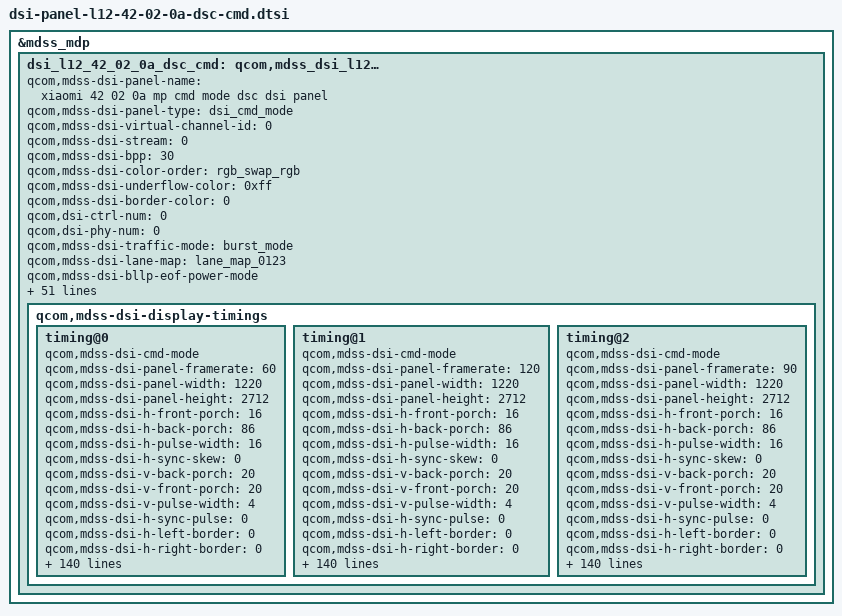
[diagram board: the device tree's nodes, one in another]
&mdss_mdp {
	dsi_l12_42_02_0a_dsc_cmd: qcom,mdss_dsi_l12_42_02_0a_dsc_cmd {
		qcom,mdss-dsi-panel-name = "xiaomi 42 02 0a mp cmd mode dsc dsi panel";
		qcom,mdss-dsi-panel-type = "dsi_cmd_mode";
		qcom,mdss-dsi-virtual-channel-id = <0>;
		qcom,mdss-dsi-stream = <0>;
		qcom,mdss-dsi-bpp = <30>;
		qcom,mdss-dsi-color-order = "rgb_swap_rgb";
		qcom,mdss-dsi-underflow-color = <0xff>;
		qcom,mdss-dsi-border-color = <0>;

		qcom,dsi-ctrl-num = <0>;
		qcom,dsi-phy-num = <0>;

		qcom,mdss-dsi-traffic-mode = "burst_mode";
		qcom,mdss-dsi-lane-map = "lane_map_0123";
		qcom,mdss-dsi-bllp-eof-power-mode;
		qcom,mdss-dsi-bllp-power-mode;
		qcom,mdss-dsi-lane-0-state;
		qcom,mdss-dsi-lane-1-state;
		qcom,mdss-dsi-lane-2-state;
		qcom,mdss-dsi-lane-3-state;
		qcom,mdss-dsi-dma-trigger = "trigger_sw";
		qcom,mdss-dsi-mdp-trigger = "none";
		qcom,mdss-dsi-reset-sequence =  <1 11>, <0 1>, <1 11>;
		qcom,mdss-pan-physical-width-dimension = <695>;
		qcom,mdss-pan-physical-height-dimension = <1545>;
		qcom,mdss-dsi-te-pin-select = <1>;
		qcom,mdss-dsi-wr-mem-start = <0x2c>;
		qcom,mdss-dsi-wr-mem-continue = <0x3c>;
		qcom,mdss-dsi-te-dcs-command = <1>;
		qcom,mdss-dsi-te-check-enable;
		qcom,mdss-dsi-te-using-te-pin;
		qcom,mdss-dsi-tx-eot-append;
		qcom,mdss-dsi-lp11-init;

		qcom,mdss-dsi-bl-inverted-dbv;
		qcom,bl-update-flag = "delay_until_first_frame";
		qcom,mdss-dsi-panel-mode-switch;

		qcom,mdss-dsi-panel-hdr-enabled;
		qcom,mdss-dsi-panel-hdr-color-primaries = <14500 15500 32000 17000 15500 30000 8000 3000>;
		qcom,mdss-dsi-panel-peak-brightness = <4200000>;
		qcom,mdss-dsi-panel-blackness-level = <3230>;
		qcom,mdss-dsi-dma-schedule-line = <1>;
		qcom,mdss-dsi-dma-schedule-window = <10>;

		qcom,mdss-dsi-display-timings {
			/* 60 Hz */
			timing@0{
				qcom,mdss-dsi-cmd-mode;
				qcom,mdss-dsi-panel-framerate = <60>;
				qcom,mdss-dsi-panel-width = <1220>;
				qcom,mdss-dsi-panel-height = <2712>;
				qcom,mdss-dsi-h-front-porch = <16>;
				qcom,mdss-dsi-h-back-porch = <86>;
				qcom,mdss-dsi-h-pulse-width = <16>;
				qcom,mdss-dsi-h-sync-skew = <0>;
				qcom,mdss-dsi-v-back-porch = <20>;
				qcom,mdss-dsi-v-front-porch = <20>;
				qcom,mdss-dsi-v-pulse-width = <4>;
				qcom,mdss-dsi-h-sync-pulse = <0>;
				qcom,mdss-dsi-h-left-border = <0>;
				qcom,mdss-dsi-h-right-border = <0>;
				qcom,mdss-dsi-v-top-border = <0>;
				qcom,mdss-dsi-v-bottom-border = <0>;
				qcom,mdss-dsi-panel-clockrate = <1100000000>;
				qcom,mdss-dsi-panel-jitter = <0x5 0x1>;
				qcom,mdss-mdp-transfer-time-us = <7300>;
				qcom,mdss-dsi-on-command = [
					/* Page 0 */
					39 00 00 00 00 00 06 F0 55 AA 52 08 00
					/* AVDD to 7.3V */
					15 00 00 40 00 00 02 6F 06
					15 00 00 40 00 00 02 B5 2C
					15 00 00 40 00 00 02 6F 0C
					15 00 00 00 00 00 02 B5 2C
					/* Page 3 */
					39 00 00 40 00 00 06 F0 55 AA 52 08 03
					/* Enable EQ in EM-CK AA */
					39 00 00 00 00 00 1E B0
						0F 00 00 0F 00 02 0F 00 00 0F 00 00 0F 00 00 0F
						00 00 0F 00 00 0F 00 00 0F 00 00 0F 00
					/* Set VGLO in SCAN-CK Blanking */
					39 00 00 40 00 00 06 F0 55 AA 52 08 05
					39 00 00 40 00 00 04 D0 00 07 10
					39 00 00 40 00 00 05 E0 00 0A 9E 02
					39 00 00 40 00 00 06 F0 55 AA 52 08 06
					39 00 00 40 00 00 06 B1 32 31 0F 32 31
					15 00 00 40 00 00 02 B3 0E
					39 00 00 40 00 00 06 B7 32 31 0F 32 31
					15 00 00 00 00 00 02 B9 0E
					/* RCN setting */
					39 00 00 40 00 00 05 FF AA 55 A5 80
					15 00 00 40 00 00 02 6F 1D
					15 00 00 40 00 00 02 F2 05
					39 00 00 40 00 00 06 F0 55 AA 52 08 00
					15 00 00 40 00 00 02 6F 1C
					39 00 00 40 00 00 04 C0 03 12 11
					39 00 00 40 00 00 06 F0 55 AA 52 08 00
					15 00 00 00 00 00 02 03 01
					/* VBP&VFP*/
					39 00 00 00 00 00 05 3B 00 14 00 14
					/* VESA ON */
					15 00 00 00 00 00 02 90 11
					/* VESA Edition */
					39 00 00 40 00 00 13 91
						AB 28 00 0C C2 00 02 32 01 31 00 08 08 BB 07 7B
						10 F0
					15 00 00 00 00 00 02 2C 00
					/* BACKLIGHT ON */
					39 00 00 40 00 00 05 51 00 00 0F FE
					15 00 00 00 00 00 02 53 20
					/* TE ON */
					15 00 00 00 00 00 02 35 00
					/* CASET/RASET Setting 1220*2712 */
					39 00 00 40 00 00 05 2A 00 00 04 C3
					39 00 00 00 00 00 05 2B 00 00 0A 97
					/* 60 Hz */
					15 00 00 40 00 00 02 2F 02
					15 00 00 40 00 00 02 5F 01
					39 00 00 40 00 00 06 F0 55 AA 52 08 00
					15 00 00 40 00 00 02 6F 09
					15 00 00 40 00 00 02 C0 00
					39 00 00 40 00 00 06 F0 55 AA 52 08 02
					15 00 00 40 00 00 02 CC 30
					15 00 00 00 14 00 02 CE 01
					15 00 00 00 00 00 02 CC 00
					/* OSC calibration */
					39 00 00 40 00 00 06 F0 55 AA 52 08 01
					39 00 00 00 00 00 08 C3 9B 01 94 D0 22 02 00
					/* round on */
					39 00 00 40 00 00 06 F0 55 AA 52 08 07
					39 00 00 00 00 00 02 C0 01
					/* ESD Error Flag, Normal High, Error Low */
					39 00 00 40 00 00 06 F0 55 AA 52 08 00
					39 00 00 40 00 00 02 6F 05
					39 00 00 00 00 00 02 BE 88
					/* Source-on-test */
					39 00 00 40 00 00 06 F0 55 AA 52 08 00
					15 00 00 40 00 00 02 6F 02
					15 00 00 00 00 00 02 C1 D8
					/* enter aod with no black */
					39 00 00 40 00 00 05 FF AA 55 A5 80
					15 00 00 40 00 00 02 6F 61
					15 00 00 00 00 00 02 F3 80
					/* demura */
					39 00 00 40 00 00 06 F0 55 AA 52 08 04
					15 00 00 40 00 00 02 6F 0D
					15 00 00 00 00 00 02 CA 05
					/* dimming step timing */
					39 01 00 40 00 00 06 F0 55 AA 52 08 00
					15 01 00 40 00 00 02 B2 98
					15 01 00 40 00 00 02 6F 02
					39 01 00 00 00 00 03 B2 0A 0A
					/* Sleep Out */
					05 00 00 00 78 00 02 11 00
					/* Display On */
					05 00 00 00 00 00 02 29 00
				];
				qcom,mdss-dsi-off-command = [
					05 00 00 00 14 00 02 28 00
					05 00 00 00 64 00 02 10 00
				];
				qcom,mdss-dsi-on-command-state = "dsi_lp_mode";
				qcom,mdss-dsi-off-command-state = "dsi_lp_mode";

				qcom,mdss-dsi-timing-switch-command = [
					/* 60 Hz cmd_1 */
					15 00 00 00 00 00 02 2F 02
					39 00 00 40 00 00 06 F0 55 AA 52 08 00
					15 00 00 40 00 00 02 6F 09
					15 00 00 40 00 00 02 C0 00
					39 00 00 40 00 00 06 F0 55 AA 52 08 02
					15 00 00 40 00 00 02 CC 30
					15 00 00 00 14 00 02 CE 01
					15 00 00 00 00 00 02 CC 00
				];
				qcom,mdss-dsi-timing-switch-command-update = <0xC0 3 1>;
				qcom,mdss-dsi-timing-switch-command-state = "dsi_hs_mode";

				qcom,mdss-dsi-nolp-command = [
					39 00 00 00 00 00 06 F0 55 AA 52 08 00
					39 00 00 00 00 00 02 B2 98
					39 00 00 00 00 00 02 65 00
					39 00 00 00 32 00 01 38
					39 00 00 00 00 00 01 2C
				];
				qcom,mdss-dsi-nolp-command-state = "dsi_lp_mode";

				qcom,compression-mode = "dsc";
				qcom,mdss-dsc-config-by-manufacture-cmd;
				qcom,mdss-dsc-version = <0x11>;
				qcom,mdss-dsc-scr-version = <0x0>;
				qcom,mdss-dsc-slice-height = <12>;
				qcom,mdss-dsc-slice-width = <610>;
				qcom,mdss-dsc-slice-per-pkt = <2>;
				qcom,mdss-dsc-bit-per-component = <10>;
				qcom,mdss-dsc-bit-per-pixel = <8>;
				qcom,mdss-dsc-block-prediction-enable;
			};

			/* 120 Hz */
			timing@1{
				qcom,mdss-dsi-cmd-mode;
				qcom,mdss-dsi-panel-framerate = <120>;
				qcom,mdss-dsi-panel-width = <1220>;
				qcom,mdss-dsi-panel-height = <2712>;
				qcom,mdss-dsi-h-front-porch = <16>;
				qcom,mdss-dsi-h-back-porch = <86>;
				qcom,mdss-dsi-h-pulse-width = <16>;
				qcom,mdss-dsi-h-sync-skew = <0>;
				qcom,mdss-dsi-v-back-porch = <20>;
				qcom,mdss-dsi-v-front-porch = <20>;
				qcom,mdss-dsi-v-pulse-width = <4>;
				qcom,mdss-dsi-h-sync-pulse = <0>;
				qcom,mdss-dsi-h-left-border = <0>;
				qcom,mdss-dsi-h-right-border = <0>;
				qcom,mdss-dsi-v-top-border = <0>;
				qcom,mdss-dsi-v-bottom-border = <0>;
				qcom,mdss-dsi-panel-clockrate = <1100000000>;
				qcom,mdss-dsi-panel-jitter = <0x5 0x1>;
				qcom,mdss-mdp-transfer-time-us = <7300>;
				qcom,mdss-dsi-on-command = [
					/* Page 0 */
					39 00 00 00 00 00 06 F0 55 AA 52 08 00
					/* AVDD to 7.3V */
					15 00 00 40 00 00 02 6F 06
					15 00 00 40 00 00 02 B5 2C
					15 00 00 40 00 00 02 6F 0C
					15 00 00 00 00 00 02 B5 2C
					/* Page 3 */
					39 00 00 40 00 00 06 F0 55 AA 52 08 03
					/* Enable EQ in EM-CK AA */
					39 00 00 00 00 00 1E B0
						0F 00 00 0F 00 02 0F 00 00 0F 00 00 0F 00 00 0F
						00 00 0F 00 00 0F 00 00 0F 00 00 0F 00
					/* Set VGLO in SCAN-CK Blanking */
					39 00 00 40 00 00 06 F0 55 AA 52 08 05
					39 00 00 40 00 00 04 D0 00 07 10
					39 00 00 40 00 00 05 E0 00 0A 9E 02
					39 00 00 40 00 00 06 F0 55 AA 52 08 06
					39 00 00 40 00 00 06 B1 32 31 0F 32 31
					15 00 00 40 00 00 02 B3 0E
					39 00 00 40 00 00 06 B7 32 31 0F 32 31
					15 00 00 00 00 00 02 B9 0E
					/* RCN setting */
					39 00 00 40 00 00 05 FF AA 55 A5 80
					15 00 00 40 00 00 02 6F 1D
					15 00 00 40 00 00 02 F2 05
					39 00 00 40 00 00 06 F0 55 AA 52 08 00
					15 00 00 40 00 00 02 6F 1C
					39 00 00 40 00 00 04 C0 03 12 11
					39 00 00 40 00 00 06 F0 55 AA 52 08 00
					15 00 00 00 00 00 02 03 01
					/* VBP&VFP*/
					39 00 00 00 00 00 05 3B 00 14 00 14
					/* VESA ON */
					15 00 00 00 00 00 02 90 11
					/* VESA Edition */
					39 00 00 40 00 00 13 91
						AB 28 00 0C C2 00 02 32 01 31 00 08 08 BB 07 7B
						10 F0
					15 00 00 00 00 00 02 2C 00
					/* BACKLIGHT ON */
					39 00 00 40 00 00 05 51 00 00 0F FE
					15 00 00 00 00 00 02 53 20
					/* TE ON */
					15 00 00 00 00 00 02 35 00
					/* CASET/RASET Setting 1220*2712 */
					39 00 00 40 00 00 05 2A 00 00 04 C3
					39 00 00 00 00 00 05 2B 00 00 0A 97
					/* 120 Hz */
					15 00 00 40 00 00 02 2F 03
					15 00 00 40 00 00 02 5F 01
					39 00 00 40 00 00 06 F0 55 AA 52 08 00
					15 00 00 40 00 00 02 6F 0A
					15 00 00 40 00 00 02 C0 20
					39 00 00 40 00 00 06 F0 55 AA 52 08 02
					15 00 00 40 00 00 02 CC 30
					15 00 00 00 14 00 02 CE 01
					15 00 00 00 00 00 02 CC 00
					/* OSC calibration */
					39 00 00 40 00 00 06 F0 55 AA 52 08 01
					39 00 00 00 00 00 08 C3 9B 01 94 D0 22 02 00
					/* round on */
					39 00 00 40 00 00 06 F0 55 AA 52 08 07
					39 00 00 00 00 00 02 C0 01
					/* ESD Error Flag, Normal High, Error Low */
					39 00 00 40 00 00 06 F0 55 AA 52 08 00
					39 00 00 40 00 00 02 6F 05
					39 00 00 00 00 00 02 BE 88
					/* Source-on-test */
					39 00 00 40 00 00 06 F0 55 AA 52 08 00
					15 00 00 40 00 00 02 6F 02
					15 00 00 00 00 00 02 C1 D8
					/* enter aod with no black */
					39 00 00 40 00 00 05 FF AA 55 A5 80
					15 00 00 40 00 00 02 6F 61
					15 00 00 00 00 00 02 F3 80
					/* demura */
					39 00 00 40 00 00 06 F0 55 AA 52 08 04
					15 00 00 40 00 00 02 6F 0D
					15 00 00 00 00 00 02 CA 05
					/* dimming step timing */
					39 01 00 40 00 00 06 F0 55 AA 52 08 00
					15 01 00 40 00 00 02 B2 98
					15 01 00 40 00 00 02 6F 02
					39 01 00 00 00 00 03 B2 0A 0A
					/* Sleep Out */
					05 00 00 00 78 00 02 11 00
					/* Display On */
					05 00 00 00 00 00 02 29 00
				];
				qcom,mdss-dsi-off-command = [
					05 00 00 00 14 00 02 28 00
					05 00 00 00 64 00 02 10 00
				];
				qcom,mdss-dsi-on-command-state = "dsi_lp_mode";
				qcom,mdss-dsi-off-command-state = "dsi_lp_mode";

				qcom,mdss-dsi-timing-switch-command = [
					/* 120 Hz cmd_1 */
					15 00 00 00 00 00 02 2F 03
					39 00 00 40 00 00 06 F0 55 AA 52 08 00
					15 00 00 40 00 00 02 6F 0A
					15 00 00 40 00 00 02 C0 20
					39 00 00 40 00 00 06 F0 55 AA 52 08 02
					15 00 00 40 00 00 02 CC 30
					15 00 00 00 0A 00 02 CE 01
					15 00 00 00 00 00 02 CC 00
				];
				qcom,mdss-dsi-timing-switch-command-update = <0xC0 3 1>;
				qcom,mdss-dsi-timing-switch-command-state = "dsi_hs_mode";

				qcom,mdss-dsi-nolp-command = [
					39 00 00 00 00 00 06 F0 55 AA 52 08 00
					39 00 00 00 00 00 02 B2 98
					39 00 00 00 00 00 02 65 00
					39 00 00 00 32 00 01 38
					39 00 00 00 00 00 01 2C
				];
				qcom,mdss-dsi-nolp-command-state = "dsi_lp_mode";

				qcom,compression-mode = "dsc";
				qcom,mdss-dsc-config-by-manufacture-cmd;
				qcom,mdss-dsc-version = <0x11>;
				qcom,mdss-dsc-scr-version = <0x0>;
				qcom,mdss-dsc-slice-height = <12>;
				qcom,mdss-dsc-slice-width = <610>;
				qcom,mdss-dsc-slice-per-pkt = <2>;
				qcom,mdss-dsc-bit-per-component = <10>;
				qcom,mdss-dsc-bit-per-pixel = <8>;
				qcom,mdss-dsc-block-prediction-enable;
			};

			/* 90 Hz */
			timing@2{
				qcom,mdss-dsi-cmd-mode;
				qcom,mdss-dsi-panel-framerate = <90>;
				qcom,mdss-dsi-panel-width = <1220>;
				qcom,mdss-dsi-panel-height = <2712>;
				qcom,mdss-dsi-h-front-porch = <16>;
				qcom,mdss-dsi-h-back-porch = <86>;
				qcom,mdss-dsi-h-pulse-width = <16>;
				qcom,mdss-dsi-h-sync-skew = <0>;
				qcom,mdss-dsi-v-back-porch = <20>;
				qcom,mdss-dsi-v-front-porch = <20>;
				qcom,mdss-dsi-v-pulse-width = <4>;
				qcom,mdss-dsi-h-sync-pulse = <0>;
				qcom,mdss-dsi-h-left-border = <0>;
				qcom,mdss-dsi-h-right-border = <0>;
				qcom,mdss-dsi-v-top-border = <0>;
				qcom,mdss-dsi-v-bottom-border = <0>;
				qcom,mdss-dsi-panel-clockrate = <1100000000>;
				qcom,mdss-dsi-panel-jitter = <0x5 0x1>;
				qcom,mdss-mdp-transfer-time-us = <7300>;
				qcom,mdss-dsi-on-command = [
					/* Page 0 */
					39 00 00 00 00 00 06 F0 55 AA 52 08 00
					/* AVDD to 7.3V */
					15 00 00 40 00 00 02 6F 06
					15 00 00 40 00 00 02 B5 2C
					15 00 00 40 00 00 02 6F 0C
					15 00 00 00 00 00 02 B5 2C
					/* Page 3 */
					39 00 00 40 00 00 06 F0 55 AA 52 08 03
					/* Enable EQ in EM-CK AA */
					39 00 00 00 00 00 1E B0
						0F 00 00 0F 00 02 0F 00 00 0F 00 00 0F 00 00 0F
						00 00 0F 00 00 0F 00 00 0F 00 00 0F 00
					/* Set VGLO in SCAN-CK Blanking */
					39 00 00 40 00 00 06 F0 55 AA 52 08 05
					39 00 00 40 00 00 04 D0 00 07 10
					39 00 00 40 00 00 05 E0 00 0A 9E 02
					39 00 00 40 00 00 06 F0 55 AA 52 08 06
					39 00 00 40 00 00 06 B1 32 31 0F 32 31
					15 00 00 40 00 00 02 B3 0E
					39 00 00 40 00 00 06 B7 32 31 0F 32 31
					15 00 00 00 00 00 02 B9 0E
					/* RCN setting */
					39 00 00 40 00 00 05 FF AA 55 A5 80
					15 00 00 40 00 00 02 6F 1D
					15 00 00 40 00 00 02 F2 05
					39 00 00 40 00 00 06 F0 55 AA 52 08 00
					15 00 00 40 00 00 02 6F 1C
					39 00 00 40 00 00 04 C0 03 12 11
					39 00 00 40 00 00 06 F0 55 AA 52 08 00
					15 00 00 00 00 00 02 03 01
					/* VBP&VFP*/
					39 00 00 00 00 00 05 3B 00 14 00 14
					/* VESA ON */
					15 00 00 00 00 00 02 90 11
					/* VESA Edition */
					39 00 00 40 00 00 13 91
						AB 28 00 0C C2 00 02 32 01 31 00 08 08 BB 07 7B
						10 F0
					15 00 00 00 00 00 02 2C 00
					/* BACKLIGHT ON */
					39 00 00 40 00 00 05 51 00 00 0F FE
					15 00 00 00 00 00 02 53 20
					/* TE ON */
					15 00 00 00 00 00 02 35 00
					/* CASET/RASET Setting 1220*2712 */
					39 00 00 40 00 00 05 2A 00 00 04 C3
					39 00 00 40 00 00 05 2B 00 00 0A 97
					/* 90 Hz */
					15 00 00 40 00 00 02 2F 04
					15 00 00 40 00 00 02 5F 01
					39 00 00 40 00 00 06 F0 55 AA 52 08 00
					15 00 00 40 00 00 02 6F 0B
					15 00 00 40 00 00 02 C0 20
					39 00 00 40 00 00 06 F0 55 AA 52 08 02
					15 00 00 40 00 00 02 CC 30
					15 00 00 00 14 00 02 CE 01
					15 00 00 00 00 00 02 CC 00
					/* OSC calibration */
					39 00 00 40 00 00 06 F0 55 AA 52 08 01
					39 00 00 00 00 00 08 C3 9B 01 94 D0 22 02 00
					/* round on */
					39 00 00 40 00 00 06 F0 55 AA 52 08 07
					39 00 00 00 00 00 02 C0 01
					/* ESD Error Flag, Normal High, Error Low */
					39 00 00 40 00 00 06 F0 55 AA 52 08 00
					39 00 00 40 00 00 02 6F 05
					39 00 00 00 00 00 02 BE 88
					/* Source-on-test */
					39 00 00 40 00 00 06 F0 55 AA 52 08 00
					15 00 00 40 00 00 02 6F 02
					15 00 00 00 00 00 02 C1 D8
					/* enter aod with no black */
					39 00 00 40 00 00 05 FF AA 55 A5 80
					15 00 00 40 00 00 02 6F 61
					15 00 00 00 00 00 02 F3 80
					/* demura */
					39 00 00 40 00 00 06 F0 55 AA 52 08 04
					15 00 00 40 00 00 02 6F 0D
					15 00 00 00 00 00 02 CA 05
					/* dimming step timing */
					39 01 00 40 00 00 06 F0 55 AA 52 08 00
					15 01 00 40 00 00 02 B2 98
					15 01 00 40 00 00 02 6F 02
					39 01 00 00 00 00 03 B2 0A 0A
					/* Sleep Out */
					05 00 00 00 78 00 02 11 00
					/* Display On */
					05 00 00 00 00 00 02 29 00
				];
				qcom,mdss-dsi-off-command = [
					05 00 00 00 14 00 02 28 00
					05 00 00 00 64 00 02 10 00
				];
				qcom,mdss-dsi-on-command-state = "dsi_lp_mode";
				qcom,mdss-dsi-off-command-state = "dsi_lp_mode";

				qcom,mdss-dsi-nolp-command = [
					39 00 00 00 00 00 06 F0 55 AA 52 08 00
					39 00 00 00 00 00 02 B2 98
					39 00 00 00 00 00 02 65 00
					39 00 00 00 32 00 01 38
					39 00 00 00 00 00 01 2C
				];
				qcom,mdss-dsi-nolp-command-state = "dsi_lp_mode";

				qcom,mdss-dsi-timing-switch-command = [
					/* 90 Hz  cmd_1*/
					15 00 00 00 00 00 02 2F 04
					39 00 00 40 00 00 06 F0 55 AA 52 08 00
					15 00 00 40 00 00 02 6F 0B
					15 00 00 40 00 00 02 C0 20
					39 00 00 40 00 00 06 F0 55 AA 52 08 02
					15 00 00 40 00 00 02 CC 30
					15 00 00 00 0D 00 02 CE 01
					15 00 00 00 00 00 02 CC 00
				];
				qcom,mdss-dsi-timing-switch-command-update = <0xC0 3 1>;
				qcom,mdss-dsi-timing-switch-command-state = "dsi_hs_mode";

				qcom,compression-mode = "dsc";
				qcom,mdss-dsc-config-by-manufacture-cmd;
				qcom,mdss-dsc-version = <0x11>;
				qcom,mdss-dsc-scr-version = <0x0>;
				qcom,mdss-dsc-slice-height = <12>;
				qcom,mdss-dsc-slice-width = <610>;
				qcom,mdss-dsc-slice-per-pkt = <2>;
				qcom,mdss-dsc-bit-per-component = <10>;
				qcom,mdss-dsc-bit-per-pixel = <8>;
				qcom,mdss-dsc-block-prediction-enable;
			};
		};
	};
};

&dsi_l12_42_02_0a_dsc_cmd {
	mi,panel-id = <0x004C3132 0x00420200>;

	/* IRQF_ONESHOT | IRQF_TRIGGER_LOW */
	mi,esd-err-irq-gpio = <&tlmm 116 0x2008>;
	mi,local-hbm-enabled;
	mi,local-hbm-white-1000nit-update-flag;
	mi,local-hbm-white-110nit-update-flag;
	mi,local-hbm-alpha-ctrl-aa-area;

	mi,panel-on-dimming-delay = <120>;
	mi,max-brightness-clone = <4095>;
	mi,normal-max-brightness-clone = <2047>;
	mi,mdss-dsi-fac-bl-max-level = <2047>;
	mi,mdss-fac-brightness-max-level = <2047>;
	mi,hbm-bl-min-level = <1>;
	mi,hbm-bl-max-level = <2047>;

	mi,doze-hbm-dbv-level = <252>;
	mi,doze-lbm-dbv-level = <20>;

	mi,thermal-dimming-flag;
	mi,ddic-round-corner-enabled;

	mi,fod-low-brightness-clone-threshold = <200>;
	mi,fod-low-brightness-lux-threshold = <3>;

	mi,flat-update-flag;
	mi,flat-need-sync-te;
	/* if gamma updated status cfg is 0x00, need to config */
	mi,flat-need-update-gamma-zero;

	mi,local-hbm-ui-ready-delay-num-frame = <4>; /* 4 frame */

	qcom,mdss-dsi-display-timings {
		timing@0{ /* 60 hz */
			/*<flat on gamma, flat off gamma>*/
			mi,mdss-flat-status-control-gamma-cfg = <0x40 0x00>;
			mi,mdss-dsi-dimmingon-command = [39 00 00 00 00 00 02 53 28];
			mi,mdss-dsi-dimmingon-command-state = "dsi_hs_mode";
			mi,mdss-dsi-dimmingoff-command = [39 00 00 00 00 00 02 53 20];
			mi,mdss-dsi-dimmingoff-command-state = "dsi_hs_mode";

			mi,mdss-dsi-hbm-fod-on-command = [
				39 00 00 00 00 00 03 51 0F FF];
			mi,mdss-dsi-hbm-fod-on-command-state = "dsi_lp_mode";
			mi,mdss-dsi-hbm-fod-off-command = [
				39 00 00 00 00 00 03 51 07 FF];
			mi,mdss-dsi-hbm-fod-off-command-state = "dsi_lp_mode";
			mi,mdss-dsi-hbm-fod-off-command-update = <0x51 0 2>;

			mi,mdss-dsi-local-hbm-normal-white-1000nit-command = [
				39 00 00 40 00 00 06 F0 55 AA 52 08 00
				39 00 00 40 00 00 02 6F 17
				/* normal dbv  0x07FF,  HBM 0x0FFF */
				39 00 00 40 00 00 03 B2 07 FF
				/* EM-1 pluse */
				39 00 00 40 00 00 02 6F 1F
				39 00 00 40 00 00 03 B2 00 50
				39 00 00 40 00 00 06 F0 55 AA 52 08 02
				/* No smooth mode */
				39 00 00 40 00 00 02 D1 01
				39 00 00 40 00 00 02 6F 08
				/* FPR area RGB[11:0] setting */
				39 00 00 40 00 00 07 D0 09 6A 08 3D 0A 18
				39 00 00 40 00 00 06 F0 55 AA 52 08 07
				39 00 00 40 00 00 02 D9 40
				/* RCN ON */
				39 00 00 40 00 00 02 C0 01
				/* normal dbv  0x07FF,  HBM 0x0FFF */
				39 00 00 40 00 00 03 51 07 FF
				39 00 00 40 00 00 02 6F 01
				/* FPR center postion x[11:0], y[11:0] */
				39 00 00 40 00 00 05 88 02 62 09 8C
				/* alpha for AA */
				39 00 00 40 00 00 03 87 11 11
				39 00 00 40 00 00 02 88 01
				39 00 00 00 00 00 02 85 01
			];
			mi,mdss-dsi-local-hbm-normal-white-1000nit-command-update = <0x87 15 2>, <0x51 12 2>, <0xD0 8 6>;
			mi,mdss-dsi-local-hbm-normal-white-1000nit-command-state = "dsi_hs_mode";

			mi,mdss-dsi-local-hbm-hlpm-white-1000nit-command = [
				/* AOD off */
				39 00 00 00 00 00 06 F0 55 AA 52 08 00
				39 00 00 00 00 00 02 B2 98
				39 00 00 00 00 00 02 65 00
				39 00 00 00 32 00 02 38 00
				39 00 00 00 00 00 02 2C 00
				/* Local HBM setting */
				39 00 00 00 00 00 06 F0 55 AA 52 08 00
				39 00 00 40 00 00 02 6F 17
				/* normal dbv  0x07FF,  HBM 0x0FFF */
				39 00 00 40 00 00 03 B2 07 FF
				/* EM-1 pluse */
				39 00 00 40 00 00 02 6F 1F
				39 00 00 40 00 00 03 B2 00 50
				39 00 00 40 00 00 06 F0 55 AA 52 08 02
				/* No smooth mode */
				39 00 00 40 00 00 02 D1 01
				39 00 00 40 00 00 02 6F 08
				/* FPR area RGB[11:0] setting */
				39 00 00 40 00 00 07 D0 09 6A 08 3D 0A 18
				39 00 00 40 00 00 06 F0 55 AA 52 08 07
				39 00 00 40 00 00 02 D9 40
				/* RCN ON */
				39 00 00 40 00 00 02 C0 01
				/* normal dbv  0x07FF,  HBM 0x0FFF */
				39 00 00 40 00 00 03 51 07 FF
				39 00 00 40 00 00 02 6F 01
				/* FPR center postion x[11:0], y[11:0] */
				39 00 00 40 00 00 05 88 02 62 09 8C
				/* alpha for AA */
				39 00 00 40 00 00 03 87 11 11
				39 00 00 40 00 00 02 88 01
				39 00 00 00 00 00 02 85 01
			];
			mi,mdss-dsi-local-hbm-hlpm-white-1000nit-command-update = <0x87 20 2>, <0x51 17 2>, <0xD0 13 6>;
			mi,mdss-dsi-local-hbm-hlpm-white-1000nit-command-state = "dsi_hs_mode";

			mi,mdss-dsi-local-hbm-normal-white-110nit-command = [
				39 00 00 40 00 00 06 F0 55 AA 52 08 00
				39 00 00 40 00 00 02 6F 17
				/* normal dbv  0x07FF,  HBM 0x0FFF */
				39 00 00 40 00 00 03 B2 07 FF
				/* EM-1 pluse */
				39 00 00 40 00 00 02 6F 1F
				39 00 00 40 00 00 03 B2 00 50
				39 00 00 40 00 00 06 F0 55 AA 52 08 02
				/* No smooth mode */
				39 00 00 40 00 00 02 D1 01
				39 00 00 40 00 00 02 6F 08
				/* FPR area RGB[11:0] setting */
				39 00 00 40 00 00 07 D0 06 13 05 60 06 8F
				39 00 00 40 00 00 06 F0 55 AA 52 08 07
				39 00 00 40 00 00 02 D9 40
				/* RCN ON */
				39 00 00 40 00 00 02 C0 01
				/* normal dbv  0x07FF,  HBM 0x0FFF */
				39 00 00 40 00 00 03 51 07 FF
				39 00 00 40 00 00 02 6F 01
				/* FPR center postion x[11:0], y[11:0] */
				39 00 00 40 00 00 05 88 02 62 09 8C
				/* alpha for AA */
				39 00 00 40 00 00 03 87 11 11
				39 00 00 40 00 00 02 88 01
				39 00 00 00 00 00 02 85 01
			];
			mi,mdss-dsi-local-hbm-normal-white-110nit-command-update  = <0x87 15 2>, <0x51 12 2>, <0xD0 8 6>;
			mi,mdss-dsi-local-hbm-normal-white-110nit-command-state = "dsi_hs_mode";

			mi,mdss-dsi-local-hbm-hlpm-white-110nit-command = [
				/* AOD off */
				39 00 00 00 00 00 06 F0 55 AA 52 08 00
				39 00 00 00 00 00 02 B2 98
				39 00 00 00 00 00 02 65 00
				39 00 00 00 32 00 02 38 00
				39 00 00 00 00 00 02 2C 00
				/* Local HBM setting */
				39 00 00 00 00 00 06 F0 55 AA 52 08 00
				39 00 00 40 00 00 02 6F 17
				/* normal dbv  0x07FF,  HBM 0x0FFF */
				39 00 00 40 00 00 03 B2 07 FF
				/* EM-1 pluse */
				39 00 00 40 00 00 02 6F 1F
				39 00 00 40 00 00 03 B2 00 50
				39 00 00 40 00 00 06 F0 55 AA 52 08 02
				/* No smooth mode */
				39 00 00 40 00 00 02 D1 01
				39 00 00 40 00 00 02 6F 08
				/* FPR area RGB[11:0] setting */
				39 00 00 40 00 00 07 D0 06 13 05 60 06 8F
				39 00 00 40 00 00 06 F0 55 AA 52 08 07
				39 00 00 40 00 00 02 D9 40
				/* RCN ON */
				39 00 00 40 00 00 02 C0 01
				/* normal dbv  0x07FF,  HBM 0x0FFF */
				39 00 00 40 00 00 03 51 07 FF
				39 00 00 40 00 00 02 6F 01
				/* FPR center postion x[11:0], y[11:0] */
				39 00 00 40 00 00 05 88 02 62 09 8C
				/* alpha for AA */
				39 00 00 40 00 00 03 87 11 11
				39 00 00 40 00 00 02 88 01
				39 00 00 00 00 00 02 85 01
			];
			mi,mdss-dsi-local-hbm-hlpm-white-110nit-command-update  = <0x87 20 2>, <0x51 17 2>, <0xD0 13 6>;
			mi,mdss-dsi-local-hbm-hlpm-white-110nit-command-state = "dsi_hs_mode";

			mi,mdss-dsi-local-hbm-normal-green-500nit-command = [
				39 00 00 00 00 00 06 F0 55 AA 52 08 00
				39 00 00 40 00 00 02 6F 17
				/* normal dbv  0x07FF,  HBM 0x0FFF */
				39 00 00 40 00 00 03 B2 07 FF
				/* EM-1 pluse */
				39 00 00 40 00 00 02 6F 1F
				39 00 00 40 00 00 03 B2 00 50
				39 00 00 40 00 00 06 F0 55 AA 52 08 02
				/* No smooth mode */
				39 00 00 40 00 00 02 D1 01
				39 00 00 40 00 00 02 6F 08
				/* FPR area RGB[11:0] setting */
				39 00 00 40 00 00 07 D0 00 00 07 F1 00 00
				39 00 00 40 00 00 06 F0 55 AA 52 08 07
				39 00 00 40 00 00 02 D9 40
				/* RCN ON */
				39 00 00 40 00 00 02 C0 01
				/* normal dbv  0x07FF,  HBM 0x0FFF */
				39 00 00 40 00 00 03 51 07 FF
				39 00 00 40 00 00 02 6F 01
				/* FPR center postion x[11:0], y[11:0] */
				39 00 00 40 00 00 05 88 02 62 09 8C
				/* alpha for AA */
				39 00 00 40 00 00 03 87 11 11
				39 00 00 40 00 00 02 88 01
				39 00 00 00 00 00 02 85 01
			];
			mi,mdss-dsi-local-hbm-normal-green-500nit-command-update  = <0x87 15 2>, <0x51 12 2>;
			mi,mdss-dsi-local-hbm-normal-green-500nit-command-state = "dsi_lp_mode";

			mi,mdss-dsi-local-hbm-off-to-normal-command = [
				/* Normal Mode DBV */
				39 00 00 40 00 00 03 51 07 FF
				/* FPR_ALPHA OFF */
				39 00 00 40 00 00 03 87 0F FF
				39 00 00 40 00 00 02 88 01
				/* FPR_OFF */
				39 00 00 00 00 00 02 86 01
			];
			mi,mdss-dsi-local-hbm-off-to-normal-command-update = <0x51 0 2>;
			mi,mdss-dsi-local-hbm-off-to-normal-command-state = "dsi_hs_mode";

			mi,mdss-dsi-local-hbm-off-to-hbm-command= [
				39 00 00 40 00 00 03 51 07 FF
				/* FPR_ALPHA OFF */
				39 00 00 40 00 00 03 87 0F FF
				39 00 00 40 00 00 02 88 01
				/* FPR_OFF */
				39 00 00 00 00 00 02 86 01
			];
			mi,mdss-dsi-local-hbm-off-to-hbm-command-update = <0x51 0 2>;
			mi,mdss-dsi-local-hbm-off-to-hbm-command-state = "dsi_hs_mode";

			mi,mdss-dsi-local-hbm-off-to-hlpm-command = [
				/* Lhbm off */
				39 00 00 40 00 00 03 51 00 00
				39 00 00 40 00 00 03 87 0F FF
				39 00 00 40 00 00 02 88 01
				39 00 00 00 00 00 02 86 01
				/* Aod hbm */
				15 00 00 40 00 00 02 5F 01
				39 00 00 40 00 00 05 51 00 00 0F FE
				39 00 00 40 00 00 06 F0 55 AA 52 08 00
				15 00 00 40 00 00 02 B2 18
				15 00 00 00 14 00 02 39 00
				15 00 00 40 00 00 02 65 01
				15 00 00 00 00 00 02 2C 00
			];
			mi,mdss-dsi-local-hbm-off-to-hlpm-command-state = "dsi_hs_mode";

			mi,mdss-dsi-local-hbm-off-to-llpm-command = [
				/* Lhbm off */
				39 00 00 40 00 00 03 51 00 00
				39 00 00 40 00 00 03 87 0F FF
				39 00 00 40 00 00 02 88 01
				39 00 00 00 00 00 02 86 01
				/* Aod lbm */
				15 00 00 40 00 00 02 5F 01
				39 00 00 40 00 00 05 51 00 00 01 55
				39 00 00 40 00 00 06 F0 55 AA 52 08 00
				15 00 00 40 00 00 02 B2 18
				15 00 00 00 14 00 02 39 00
				15 00 00 40 00 00 02 65 01
				15 00 00 00 00 00 02 2C 00
			];
			mi,mdss-dsi-local-hbm-off-to-llpm-command-state = "dsi_hs_mode";

			mi,mdss-dsi-doze-hbm-command = [
				15 00 00 40 00 00 02 5F 01
				39 00 00 40 00 00 05 51 00 00 0F FE
				39 00 00 40 00 00 06 F0 55 AA 52 08 00
				15 00 00 40 00 00 02 B2 18
				15 00 00 00 14 00 02 39 00
				15 00 00 40 00 00 02 65 01
				15 00 00 00 00 00 02 2C 00
			];
			mi,mdss-dsi-doze-hbm-command-state = "dsi_lp_mode";
			mi,mdss-dsi-doze-lbm-command = [
				15 00 00 40 00 00 02 5F 01
				39 00 00 40 00 00 05 51 00 00 01 55
				39 00 00 40 00 00 06 F0 55 AA 52 08 00
				15 00 00 40 00 00 02 B2 18
				15 00 00 00 14 00 02 39 00
				15 00 00 40 00 00 02 65 01
				15 00 00 00 00 00 02 2C 00
			];
			mi,mdss-dsi-doze-lbm-command-state = "dsi_lp_mode";
			mi,mdss-dsi-doze-hbm-nolp-command = [
				39 00 00 00 00 00 06 F0 55 AA 52 08 00
				39 00 00 00 00 00 02 B2 98
				39 00 00 00 00 00 02 65 00
				39 00 00 00 32 00 01 38
				39 00 00 00 00 00 01 2C
			];
			mi,mdss-dsi-doze-hbm-nolp-command-state = "dsi_lp_mode";
			mi,mdss-dsi-doze-lbm-nolp-command = [
				39 00 00 00 00 00 06 F0 55 AA 52 08 00
				39 00 00 00 00 00 02 B2 98
				39 00 00 00 00 00 02 65 00
				39 00 00 00 32 00 01 38
				39 00 00 00 00 00 01 2C
			];
			mi,mdss-dsi-doze-lbm-nolp-command-state = "dsi_lp_mode";

			mi,mdss-dsi-flat-mode-on-command = [
				/* 60 Hz gir cmd_1 */
				15 00 00 00 00 00 02 2F 02
				15 00 00 60 00 00 02 5F 00
				39 00 00 60 00 00 06 F0 55 AA 52 08 00
				15 00 00 60 00 00 02 6F 09
				15 00 00 60 00 00 02 C0 40
				39 00 00 60 00 00 06 F0 55 AA 52 08 02
				15 00 00 60 00 00 02 CC 30
				15 00 00 20 14 00 02 CE 01
			];
			mi,mdss-dsi-flat-mode-on-command-state = "dsi_lp_mode";

			mi,mdss-dsi-flat-mode-on-sec-command = [
				/* 60 Hz gir cmd_2*/
				39 00 00 00 00 00 06 F0 55 AA 52 08 02
				15 00 00 00 00 00 02 CC 00
			];
			mi,mdss-dsi-flat-mode-on-sec-command-state = "dsi_lp_mode";

			mi,mdss-dsi-flat-mode-off-command = [
				/* 60 Hz gir cmd_1,need sync te*/
				15 00 00 00 00 00 02 2F 02
				15 00 00 60 00 00 02 5F 01
				39 00 00 60 00 00 06 F0 55 AA 52 08 00
				15 00 00 60 00 00 02 6F 09
				15 00 00 60 00 00 02 C0 00
				39 00 00 60 00 00 06 F0 55 AA 52 08 02
				15 00 00 60 00 00 02 CC 30
				15 00 00 20 14 00 02 CE 01
			];
			mi,mdss-dsi-flat-mode-off-command-state = "dsi_lp_mode";

			mi,mdss-dsi-flat-mode-off-sec-command = [
				/* 60 Hz gir cmd_2*/
				39 00 00 00 00 00 06 F0 55 AA 52 08 02
				15 00 00 00 00 00 02 CC 00
			];
			mi,mdss-dsi-flat-mode-off-sec-command-state = "dsi_lp_mode";

			mi,mdss-dsi-round-corner-on-command = [
				/* Page 07 */
				39 00 00 00 00 00 06 F0 55 AA 52 08 07
				/* Round on */
				39 00 00 00 00 00 02 C0 01
			];
			mi,mdss-dsi-round-corner-on-command-state = "dsi_lp_mode";

			mi,mdss-dsi-round-corner-off-command = [
				/* Page 07 */
				39 00 00 00 00 00 06 F0 55 AA 52 08 07
				/* Round off */
				39 00 00 00 00 00 02 C0 00
			];
			mi,mdss-dsi-round-corner-off-command-state = "dsi_lp_mode";

		};
		timing@1{ /* 120 hz */
			/*<flat on gamma, flat off gamma>*/
			mi,mdss-flat-status-control-gamma-cfg = <0x60 0x20>;
			mi,mdss-dsi-dimmingon-command = [39 00 00 00 00 00 02 53 28];
			mi,mdss-dsi-dimmingon-command-state = "dsi_hs_mode";
			mi,mdss-dsi-dimmingoff-command = [39 00 00 00 00 00 02 53 20];
			mi,mdss-dsi-dimmingoff-command-state = "dsi_hs_mode";

			mi,mdss-dsi-hbm-fod-on-command = [
				39 00 00 00 00 00 03 51 0F FF];
			mi,mdss-dsi-hbm-fod-on-command-state = "dsi_lp_mode";
			mi,mdss-dsi-hbm-fod-off-command = [
				39 00 00 00 00 00 03 51 07 FF];
			mi,mdss-dsi-hbm-fod-off-command-state = "dsi_lp_mode";
			mi,mdss-dsi-hbm-fod-off-command-update = <0x51 0 2>;

			mi,mdss-dsi-local-hbm-normal-white-1000nit-command = [
				39 00 00 40 00 00 06 F0 55 AA 52 08 00
				39 00 00 40 00 00 02 6F 17
				/* normal dbv  0x07FF,  HBM 0x0FFF */
				39 00 00 40 00 00 03 B2 07 FF
				/* EM-1 pluse */
				39 00 00 40 00 00 02 6F 1F
				39 00 00 40 00 00 03 B2 00 50
				39 00 00 40 00 00 06 F0 55 AA 52 08 02
				/* No smooth mode */
				39 00 00 40 00 00 02 D1 01
				39 00 00 40 00 00 02 6F 08
				/* FPR area RGB[11:0] setting */
				39 00 00 40 00 00 07 D0 09 6A 08 3D 0A 18
				39 00 00 40 00 00 06 F0 55 AA 52 08 07
				39 00 00 40 00 00 02 D9 40
				/* RCN ON */
				39 00 00 40 00 00 02 C0 01
				/* normal dbv  0x07FF,  HBM 0x0FFF */
				39 00 00 40 00 00 03 51 07 FF
				39 00 00 40 00 00 02 6F 01
				/* FPR center postion x[11:0], y[11:0] */
				39 00 00 40 00 00 05 88 02 62 09 8C
				/* alpha for AA */
				39 00 00 40 00 00 03 87 11 11
				39 00 00 40 00 00 02 88 01
				39 00 00 00 00 00 02 85 01
			];
			mi,mdss-dsi-local-hbm-normal-white-1000nit-command-update = <0x87 15 2>, <0x51 12 2>, <0xD0 8 6>;
			mi,mdss-dsi-local-hbm-normal-white-1000nit-command-state = "dsi_hs_mode";

			mi,mdss-dsi-local-hbm-hlpm-white-1000nit-command = [
				/* AOD off */
				39 00 00 00 00 00 06 F0 55 AA 52 08 00
				39 00 00 00 00 00 02 B2 98
				39 00 00 00 00 00 02 65 00
				39 00 00 00 32 00 02 38 00
				39 00 00 00 00 00 02 2C 00
				/* Local HBM setting */
				39 00 00 00 00 00 06 F0 55 AA 52 08 00
				39 00 00 40 00 00 02 6F 17
				/* normal dbv  0x07FF,  HBM 0x0FFF */
				39 00 00 40 00 00 03 B2 07 FF
				/* EM-1 pluse */
				39 00 00 40 00 00 02 6F 1F
				39 00 00 40 00 00 03 B2 00 50
				39 00 00 40 00 00 06 F0 55 AA 52 08 02
				/* No smooth mode */
				39 00 00 40 00 00 02 D1 01
				39 00 00 40 00 00 02 6F 08
				/* FPR area RGB[11:0] setting */
				39 00 00 40 00 00 07 D0 09 6A 08 3D 0A 18
				39 00 00 40 00 00 06 F0 55 AA 52 08 07
				39 00 00 40 00 00 02 D9 40
				/* RCN ON */
				39 00 00 40 00 00 02 C0 01
				/* normal dbv  0x07FF,  HBM 0x0FFF */
				39 00 00 40 00 00 03 51 07 FF
				39 00 00 40 00 00 02 6F 01
				/* FPR center postion x[11:0], y[11:0] */
				39 00 00 40 00 00 05 88 02 62 09 8C
				/* alpha for AA */
				39 00 00 40 00 00 03 87 11 11
				39 00 00 40 00 00 02 88 01
				39 00 00 00 00 00 02 85 01
			];
			mi,mdss-dsi-local-hbm-hlpm-white-1000nit-command-update = <0x87 20 2>, <0x51 17 2>, <0xD0 13 6>;
			mi,mdss-dsi-local-hbm-hlpm-white-1000nit-command-state = "dsi_hs_mode";

			mi,mdss-dsi-local-hbm-normal-white-110nit-command = [
				39 00 00 40 00 00 06 F0 55 AA 52 08 00
				39 00 00 40 00 00 02 6F 17
				/* normal dbv  0x07FF,  HBM 0x0FFF */
				39 00 00 40 00 00 03 B2 07 FF
				/* EM-1 pluse */
				39 00 00 40 00 00 02 6F 1F
				39 00 00 40 00 00 03 B2 00 50
				39 00 00 40 00 00 06 F0 55 AA 52 08 02
				/* No smooth mode */
				39 00 00 40 00 00 02 D1 01
				39 00 00 40 00 00 02 6F 08
				/* FPR area RGB[11:0] setting */
				39 00 00 40 00 00 07 D0 06 13 05 60 06 8F
				39 00 00 40 00 00 06 F0 55 AA 52 08 07
				39 00 00 40 00 00 02 D9 40
				/* RCN ON */
				39 00 00 40 00 00 02 C0 01
				/* normal dbv  0x07FF,  HBM 0x0FFF */
				39 00 00 40 00 00 03 51 07 FF
				39 00 00 40 00 00 02 6F 01
				/* FPR center postion x[11:0], y[11:0] */
				39 00 00 40 00 00 05 88 02 62 09 8C
				/* alpha for AA */
				39 00 00 40 00 00 03 87 11 11
				39 00 00 40 00 00 02 88 01
				39 00 00 00 00 00 02 85 01
			];
			mi,mdss-dsi-local-hbm-normal-white-110nit-command-update  = <0x87 15 2>, <0x51 12 2>, <0xD0 8 6>;
			mi,mdss-dsi-local-hbm-normal-white-110nit-command-state = "dsi_hs_mode";

			mi,mdss-dsi-local-hbm-hlpm-white-110nit-command = [
				/* AOD off */
				39 00 00 00 00 00 06 F0 55 AA 52 08 00
				39 00 00 00 00 00 02 B2 98
				39 00 00 00 00 00 02 65 00
				39 00 00 00 32 00 02 38 00
				39 00 00 00 00 00 02 2C 00
				/* Local HBM setting */
				39 00 00 00 00 00 06 F0 55 AA 52 08 00
				39 00 00 40 00 00 02 6F 17
				/* normal dbv  0x07FF,  HBM 0x0FFF */
				39 00 00 40 00 00 03 B2 07 FF
				/* EM-1 pluse */
				39 00 00 40 00 00 02 6F 1F
				39 00 00 40 00 00 03 B2 00 50
				39 00 00 40 00 00 06 F0 55 AA 52 08 02
				/* No smooth mode */
				39 00 00 40 00 00 02 D1 01
				39 00 00 40 00 00 02 6F 08
				/* FPR area RGB[11:0] setting */
				39 00 00 40 00 00 07 D0 06 13 05 60 06 8F
				39 00 00 40 00 00 06 F0 55 AA 52 08 07
				39 00 00 40 00 00 02 D9 40
				/* RCN ON */
				39 00 00 40 00 00 02 C0 01
				/* normal dbv  0x07FF,  HBM 0x0FFF */
				39 00 00 40 00 00 03 51 07 FF
				39 00 00 40 00 00 02 6F 01
				/* FPR center postion x[11:0], y[11:0] */
				39 00 00 40 00 00 05 88 02 62 09 8C
				/* alpha for AA */
				39 00 00 40 00 00 03 87 11 11
				39 00 00 40 00 00 02 88 01
				39 00 00 00 00 00 02 85 01
			];
			mi,mdss-dsi-local-hbm-hlpm-white-110nit-command-update  = <0x87 20 2>, <0x51 17 2>, <0xD0 13 6>;
			mi,mdss-dsi-local-hbm-hlpm-white-110nit-command-state = "dsi_hs_mode";

			mi,mdss-dsi-local-hbm-normal-green-500nit-command = [
				39 00 00 00 00 00 06 F0 55 AA 52 08 00
				39 00 00 40 00 00 02 6F 17
				/* normal dbv  0x07FF,  HBM 0x0FFF */
				39 00 00 40 00 00 03 B2 07 FF
				/* EM-1 pluse */
				39 00 00 40 00 00 02 6F 1F
				39 00 00 40 00 00 03 B2 00 50
				39 00 00 40 00 00 06 F0 55 AA 52 08 02
				/* No smooth mode */
				39 00 00 40 00 00 02 D1 01
				39 00 00 40 00 00 02 6F 08
				/* FPR area RGB[11:0] setting */
				39 00 00 40 00 00 07 D0 00 00 07 F1 00 00
				39 00 00 40 00 00 06 F0 55 AA 52 08 07
				39 00 00 40 00 00 02 D9 40
				/* RCN ON */
				39 00 00 40 00 00 02 C0 01
				/* normal dbv  0x07FF,  HBM 0x0FFF */
				39 00 00 40 00 00 03 51 07 FF
				39 00 00 40 00 00 02 6F 01
				/* FPR center postion x[11:0], y[11:0] */
				39 00 00 40 00 00 05 88 02 62 09 8C
				/* alpha for AA */
				39 00 00 40 00 00 03 87 11 11
				39 00 00 40 00 00 02 88 01
				39 00 00 00 00 00 02 85 01
			];
			mi,mdss-dsi-local-hbm-normal-green-500nit-command-update  = <0x87 15 2>, <0x51 12 2>;
			mi,mdss-dsi-local-hbm-normal-green-500nit-command-state = "dsi_lp_mode";

			mi,mdss-dsi-local-hbm-off-to-normal-command = [
				/* Normal Mode DBV */
				39 00 00 40 00 00 03 51 07 FF
				/* FPR_ALPHA OFF */
				39 00 00 40 00 00 03 87 0F FF
				39 00 00 40 00 00 02 88 01
				/* FPR_OFF */
				39 00 00 00 00 00 02 86 01
			];
			mi,mdss-dsi-local-hbm-off-to-normal-command-update = <0x51 0 2>;
			mi,mdss-dsi-local-hbm-off-to-normal-command-state = "dsi_hs_mode";

			mi,mdss-dsi-local-hbm-off-to-hbm-command= [
				39 00 00 40 00 00 03 51 07 FF
				/* FPR_ALPHA OFF */
				39 00 00 40 00 00 03 87 0F FF
				39 00 00 40 00 00 02 88 01
				/* FPR_OFF */
				39 00 00 00 00 00 02 86 01
			];
			mi,mdss-dsi-local-hbm-off-to-hbm-command-update = <0x51 0 2>;
			mi,mdss-dsi-local-hbm-off-to-hbm-command-state = "dsi_hs_mode";

			mi,mdss-dsi-local-hbm-off-to-hlpm-command = [
				/* Lhbm off */
				39 00 00 40 00 00 03 51 00 00
				39 00 00 40 00 00 03 87 0F FF
				39 00 00 40 00 00 02 88 01
				39 00 00 00 00 00 02 86 01
				/* Aod hbm */
				15 00 00 40 00 00 02 5F 01
				39 00 00 40 00 00 05 51 00 00 0F FE
				39 00 00 40 00 00 06 F0 55 AA 52 08 00
				15 00 00 40 00 00 02 B2 18
				15 00 00 00 14 00 02 39 00
				15 00 00 40 00 00 02 65 01
				15 00 00 00 00 00 02 2C 00
			];
			mi,mdss-dsi-local-hbm-off-to-hlpm-command-state = "dsi_hs_mode";

			mi,mdss-dsi-local-hbm-off-to-llpm-command = [
				/* Lhbm off */
				39 00 00 40 00 00 03 51 00 00
				39 00 00 40 00 00 03 87 0F FF
				39 00 00 40 00 00 02 88 01
				39 00 00 00 00 00 02 86 01
				/* Aod lbm */
				15 00 00 40 00 00 02 5F 01
				39 00 00 40 00 00 05 51 00 00 01 55
				39 00 00 40 00 00 06 F0 55 AA 52 08 00
				15 00 00 40 00 00 02 B2 18
				15 00 00 00 14 00 02 39 00
				15 00 00 40 00 00 02 65 01
				15 00 00 00 00 00 02 2C 00
			];
			mi,mdss-dsi-local-hbm-off-to-llpm-command-state = "dsi_hs_mode";

			mi,mdss-dsi-doze-hbm-command = [
				15 00 00 40 00 00 02 5F 01
				39 00 00 40 00 00 05 51 00 00 0F FE
				39 00 00 40 00 00 06 F0 55 AA 52 08 00
				15 00 00 40 00 00 02 B2 18
				15 00 00 00 14 00 02 39 00
				15 00 00 40 00 00 02 65 01
				15 00 00 00 00 00 02 2C 00
			];
			mi,mdss-dsi-doze-hbm-command-state = "dsi_lp_mode";
			mi,mdss-dsi-doze-lbm-command = [
				15 00 00 40 00 00 02 5F 01
				39 00 00 40 00 00 05 51 00 00 01 55
				39 00 00 40 00 00 06 F0 55 AA 52 08 00
				15 00 00 40 00 00 02 B2 18
				15 00 00 00 14 00 02 39 00
				15 00 00 40 00 00 02 65 01
				15 00 00 00 00 00 02 2C 00
			];
			mi,mdss-dsi-doze-lbm-command-state = "dsi_lp_mode";
			mi,mdss-dsi-doze-hbm-nolp-command = [
				39 00 00 00 00 00 06 F0 55 AA 52 08 00
				39 00 00 00 00 00 02 B2 98
				39 00 00 00 00 00 02 65 00
				39 00 00 00 32 00 01 38
				39 00 00 00 00 00 01 2C
			];
			mi,mdss-dsi-doze-hbm-nolp-command-state = "dsi_lp_mode";
			mi,mdss-dsi-doze-lbm-nolp-command = [
				39 00 00 00 00 00 06 F0 55 AA 52 08 00
				39 00 00 00 00 00 02 B2 98
				39 00 00 00 00 00 02 65 00
				39 00 00 00 32 00 01 38
				39 00 00 00 00 00 01 2C
			];
			mi,mdss-dsi-doze-lbm-nolp-command-state = "dsi_lp_mode";

			mi,mdss-dsi-flat-mode-on-command = [
				/* 120 Hz gir cmd_1*/
				15 00 00 00 00 00 02 2F 03
				15 00 00 60 00 00 02 5F 00
				39 00 00 60 00 00 06 F0 55 AA 52 08 00
				15 00 00 60 00 00 02 6F 0A
				15 00 00 60 00 00 02 C0 60
				39 00 00 60 00 00 06 F0 55 AA 52 08 02
				15 00 00 60 00 00 02 CC 30
				15 00 00 20 14 00 02 CE 01
			];
			mi,mdss-dsi-flat-mode-on-command-state = "dsi_lp_mode";

			mi,mdss-dsi-flat-mode-on-sec-command = [
				/* 120 Hz gir cmd_2*/
				39 00 00 00 00 00 06 F0 55 AA 52 08 02
				15 00 00 00 00 00 02 CC 00
			];
			mi,mdss-dsi-flat-mode-on-sec-command-state = "dsi_lp_mode";

			mi,mdss-dsi-flat-mode-off-command = [
				/* 120 Hz gir cmd_1*/
				15 00 00 00 00 00 02 2F 03
				15 00 00 60 00 00 02 5F 01
				39 00 00 60 00 00 06 F0 55 AA 52 08 00
				15 00 00 60 00 00 02 6F 0A
				15 00 00 60 00 00 02 C0 20
				39 00 00 60 00 00 06 F0 55 AA 52 08 02
				15 00 00 60 00 00 02 CC 30
				15 00 00 20 14 00 02 CE 01
			];
			mi,mdss-dsi-flat-mode-off-command-state = "dsi_lp_mode";

			mi,mdss-dsi-flat-mode-off-sec-command = [
				/* 120 Hz gir cmd_2*/
				39 00 00 00 00 00 06 F0 55 AA 52 08 02
				15 00 00 00 00 00 02 CC 00
			];
			mi,mdss-dsi-flat-mode-off-sec-command-state = "dsi_lp_mode";

			mi,mdss-dsi-round-corner-on-command = [
				/* Page 07 */
				39 00 00 00 00 00 06 F0 55 AA 52 08 07
				/* Round on */
				39 00 00 00 00 00 02 C0 01
			];
			mi,mdss-dsi-round-corner-on-command-state = "dsi_lp_mode";

			mi,mdss-dsi-round-corner-off-command = [
				/* Page 07 */
				39 00 00 00 00 00 06 F0 55 AA 52 08 07
				/* Round off */
				39 00 00 00 00 00 02 C0 00
			];
			mi,mdss-dsi-round-corner-off-command-state = "dsi_lp_mode";
		};
		timing@2{ /* 90 hz */
			/*<flat on gamma, flat off gamma>*/
			mi,mdss-flat-status-control-gamma-cfg = <0x60 0x20>;
			mi,mdss-dsi-dimmingon-command = [39 00 00 00 00 00 02 53 28];
			mi,mdss-dsi-dimmingon-command-state = "dsi_hs_mode";
			mi,mdss-dsi-dimmingoff-command = [39 00 00 00 00 00 02 53 20];
			mi,mdss-dsi-dimmingoff-command-state = "dsi_hs_mode";

			mi,mdss-dsi-hbm-fod-on-command = [
				39 00 00 00 00 00 03 51 0F FF];
			mi,mdss-dsi-hbm-fod-on-command-state = "dsi_lp_mode";
			mi,mdss-dsi-hbm-fod-off-command = [
				39 00 00 00 00 00 03 51 07 FF];
			mi,mdss-dsi-hbm-fod-off-command-state = "dsi_lp_mode";
			mi,mdss-dsi-hbm-fod-off-command-update = <0x51 0 2>;

			mi,mdss-dsi-local-hbm-normal-white-1000nit-command = [
				39 00 00 40 00 00 06 F0 55 AA 52 08 00
				39 00 00 40 00 00 02 6F 17
				/* normal dbv  0x07FF,  HBM 0x0FFF */
				39 00 00 40 00 00 03 B2 07 FF
				/* EM-1 pluse */
				39 00 00 40 00 00 02 6F 1F
				39 00 00 40 00 00 03 B2 00 50
				39 00 00 40 00 00 06 F0 55 AA 52 08 02
				/* No smooth mode */
				39 00 00 40 00 00 02 D1 01
				39 00 00 40 00 00 02 6F 08
				/* FPR area RGB[11:0] setting */
				39 00 00 40 00 00 07 D0 09 6A 08 3D 0A 18
				39 00 00 40 00 00 06 F0 55 AA 52 08 07
				39 00 00 40 00 00 02 D9 40
				/* RCN ON */
				39 00 00 40 00 00 02 C0 01
				/* normal dbv  0x07FF,  HBM 0x0FFF */
				39 00 00 40 00 00 03 51 07 FF
				39 00 00 40 00 00 02 6F 01
				/* FPR center postion x[11:0], y[11:0] */
				39 00 00 40 00 00 05 88 02 62 09 8C
				/* alpha for AA */
				39 00 00 40 00 00 03 87 11 11
				39 00 00 40 00 00 02 88 01
				39 00 00 00 00 00 02 85 01
			];
			mi,mdss-dsi-local-hbm-normal-white-1000nit-command-update = <0x87 15 2>, <0x51 12 2>, <0xD0 8 6>;
			mi,mdss-dsi-local-hbm-normal-white-1000nit-command-state = "dsi_hs_mode";

			mi,mdss-dsi-local-hbm-hlpm-white-1000nit-command = [
				/* AOD off */
				39 00 00 00 00 00 06 F0 55 AA 52 08 00
				39 00 00 00 00 00 02 B2 98
				39 00 00 00 00 00 02 65 00
				39 00 00 00 32 00 02 38 00
				39 00 00 00 00 00 02 2C 00
				/* Local HBM setting */
				39 00 00 00 00 00 06 F0 55 AA 52 08 00
				39 00 00 40 00 00 02 6F 17
				/* normal dbv  0x07FF,  HBM 0x0FFF */
				39 00 00 40 00 00 03 B2 07 FF
				/* EM-1 pluse */
				39 00 00 40 00 00 02 6F 1F
				39 00 00 40 00 00 03 B2 00 50
				39 00 00 40 00 00 06 F0 55 AA 52 08 02
				/* No smooth mode */
				39 00 00 40 00 00 02 D1 01
				39 00 00 40 00 00 02 6F 08
				/* FPR area RGB[11:0] setting */
				39 00 00 40 00 00 07 D0 09 6A 08 3D 0A 18
				39 00 00 40 00 00 06 F0 55 AA 52 08 07
				39 00 00 40 00 00 02 D9 40
				/* RCN ON */
				39 00 00 40 00 00 02 C0 01
				/* normal dbv  0x07FF,  HBM 0x0FFF */
				39 00 00 40 00 00 03 51 07 FF
				39 00 00 40 00 00 02 6F 01
				/* FPR center postion x[11:0], y[11:0] */
				39 00 00 40 00 00 05 88 02 62 09 8C
				/* alpha for AA */
				39 00 00 40 00 00 03 87 11 11
				39 00 00 40 00 00 02 88 01
				39 00 00 00 00 00 02 85 01
			];
			mi,mdss-dsi-local-hbm-hlpm-white-1000nit-command-update = <0x87 20 2>, <0x51 17 2>, <0xD0 13 6>;
			mi,mdss-dsi-local-hbm-hlpm-white-1000nit-command-state = "dsi_hs_mode";

			mi,mdss-dsi-local-hbm-normal-white-110nit-command = [
				39 00 00 40 00 00 06 F0 55 AA 52 08 00
				39 00 00 40 00 00 02 6F 17
				/* normal dbv  0x07FF,  HBM 0x0FFF */
				39 00 00 40 00 00 03 B2 07 FF
				/* EM-1 pluse */
				39 00 00 40 00 00 02 6F 1F
				39 00 00 40 00 00 03 B2 00 50
				39 00 00 40 00 00 06 F0 55 AA 52 08 02
				/* No smooth mode */
				39 00 00 40 00 00 02 D1 01
				39 00 00 40 00 00 02 6F 08
				/* FPR area RGB[11:0] setting */
				39 00 00 40 00 00 07 D0 06 13 05 60 06 8F
				39 00 00 40 00 00 06 F0 55 AA 52 08 07
				39 00 00 40 00 00 02 D9 40
				/* RCN ON */
				39 00 00 40 00 00 02 C0 01
				/* normal dbv  0x07FF,  HBM 0x0FFF */
				39 00 00 40 00 00 03 51 07 FF
				39 00 00 40 00 00 02 6F 01
				/* FPR center postion x[11:0], y[11:0] */
				39 00 00 40 00 00 05 88 02 62 09 8C
				/* alpha for AA */
				39 00 00 40 00 00 03 87 11 11
				39 00 00 40 00 00 02 88 01
				39 00 00 00 00 00 02 85 01
			];
			mi,mdss-dsi-local-hbm-normal-white-110nit-command-update  = <0x87 15 2>, <0x51 12 2>, <0xD0 8 6>;
			mi,mdss-dsi-local-hbm-normal-white-110nit-command-state = "dsi_hs_mode";

			mi,mdss-dsi-local-hbm-hlpm-white-110nit-command = [
				/* AOD off */
				39 00 00 00 00 00 06 F0 55 AA 52 08 00
				39 00 00 00 00 00 02 B2 98
				39 00 00 00 00 00 02 65 00
				39 00 00 00 32 00 01 38
				39 00 00 00 00 00 01 2C
				/* Local HBM setting */
				39 00 00 00 00 00 06 F0 55 AA 52 08 00
				39 00 00 40 00 00 02 6F 17
				/* normal dbv  0x07FF,  HBM 0x0FFF */
				39 00 00 40 00 00 03 B2 07 FF
				/* EM-1 pluse */
				39 00 00 40 00 00 02 6F 1F
				39 00 00 40 00 00 03 B2 00 50
				39 00 00 40 00 00 06 F0 55 AA 52 08 02
				/* No smooth mode */
				39 00 00 40 00 00 02 D1 01
				39 00 00 40 00 00 02 6F 08
				/* FPR area RGB[11:0] setting */
				39 00 00 40 00 00 07 D0 06 13 05 60 06 8F
				39 00 00 40 00 00 06 F0 55 AA 52 08 07
				39 00 00 40 00 00 02 D9 40
				/* RCN ON */
				39 00 00 40 00 00 02 C0 01
				/* normal dbv  0x07FF,  HBM 0x0FFF */
				39 00 00 40 00 00 03 51 07 FF
				39 00 00 40 00 00 02 6F 01
				/* FPR center postion x[11:0], y[11:0] */
				39 00 00 40 00 00 05 88 02 62 09 8C
				/* alpha for AA */
				39 00 00 40 00 00 03 87 11 11
				39 00 00 40 00 00 02 88 01
				39 00 00 00 00 00 02 85 01
			];
			mi,mdss-dsi-local-hbm-hlpm-white-110nit-command-update  = <0x87 20 2>, <0x51 17 2>, <0xD0 13 6>;
			mi,mdss-dsi-local-hbm-hlpm-white-110nit-command-state = "dsi_hs_mode";

			mi,mdss-dsi-local-hbm-normal-green-500nit-command = [
				39 00 00 00 00 00 06 F0 55 AA 52 08 00
				39 00 00 40 00 00 02 6F 17
				/* normal dbv  0x07FF,  HBM 0x0FFF */
				39 00 00 40 00 00 03 B2 07 FF
				/* EM-1 pluse */
				39 00 00 40 00 00 02 6F 1F
				39 00 00 40 00 00 03 B2 00 50
				39 00 00 40 00 00 06 F0 55 AA 52 08 02
				/* No smooth mode */
				39 00 00 40 00 00 02 D1 01
				39 00 00 40 00 00 02 6F 08
				/* FPR area RGB[11:0] setting */
				39 00 00 40 00 00 07 D0 00 00 07 F1 00 00
				39 00 00 40 00 00 06 F0 55 AA 52 08 07
				39 00 00 40 00 00 02 D9 40
				/* RCN ON */
				39 00 00 40 00 00 02 C0 01
				/* normal dbv  0x07FF,  HBM 0x0FFF */
				39 00 00 40 00 00 03 51 07 FF
				39 00 00 40 00 00 02 6F 01
				/* FPR center postion x[11:0], y[11:0] */
				39 00 00 40 00 00 05 88 02 62 09 8C
				/* alpha for AA */
				39 00 00 40 00 00 03 87 11 11
				39 00 00 40 00 00 02 88 01
				39 00 00 00 00 00 02 85 01
			];
			mi,mdss-dsi-local-hbm-normal-green-500nit-command-update  = <0x87 15 2>, <0x51 12 2>;
			mi,mdss-dsi-local-hbm-normal-green-500nit-command-state = "dsi_lp_mode";

			mi,mdss-dsi-local-hbm-off-to-normal-command = [
				/* Normal Mode DBV */
				39 00 00 40 00 00 03 51 07 FF
				/* FPR_ALPHA OFF */
				39 00 00 40 00 00 03 87 0F FF
				39 00 00 40 00 00 02 88 01
				/* FPR_OFF */
				39 00 00 00 00 00 02 86 01
			];
			mi,mdss-dsi-local-hbm-off-to-normal-command-update = <0x51 0 2>;
			mi,mdss-dsi-local-hbm-off-to-normal-command-state = "dsi_hs_mode";

			mi,mdss-dsi-local-hbm-off-to-hbm-command= [
				39 00 00 40 00 00 03 51 07 FF
				/* FPR_ALPHA OFF */
				39 00 00 40 00 00 03 87 0F FF
				39 00 00 40 00 00 02 88 01
				/* FPR_OFF */
				39 00 00 00 00 00 02 86 01
			];
			mi,mdss-dsi-local-hbm-off-to-hbm-command-update = <0x51 0 2>;
			mi,mdss-dsi-local-hbm-off-to-hbm-command-state = "dsi_hs_mode";

			mi,mdss-dsi-local-hbm-off-to-hlpm-command = [
				/* Lhbm off */
				39 00 00 40 00 00 03 51 00 00
				39 00 00 40 00 00 03 87 0F FF
				39 00 00 40 00 00 02 88 01
				39 00 00 00 00 00 02 86 01
				/* Aod hbm */
				15 00 00 40 00 00 02 5F 01
				39 00 00 40 00 00 05 51 00 00 0F FE
				39 00 00 40 00 00 06 F0 55 AA 52 08 00
				15 00 00 40 00 00 02 B2 18
				15 00 00 00 14 00 02 39 00
				15 00 00 40 00 00 02 65 01
				15 00 00 00 00 00 02 2C 00
			];
			mi,mdss-dsi-local-hbm-off-to-hlpm-command-state = "dsi_hs_mode";

			mi,mdss-dsi-local-hbm-off-to-llpm-command = [
				/* Lhbm off */
				39 00 00 40 00 00 03 51 00 00
				39 00 00 40 00 00 03 87 0F FF
				39 00 00 40 00 00 02 88 01
				39 00 00 00 00 00 02 86 01
				/* Aod lbm */
				15 00 00 40 00 00 02 5F 01
				39 00 00 40 00 00 05 51 00 00 01 55
				39 00 00 40 00 00 06 F0 55 AA 52 08 00
				15 00 00 40 00 00 02 B2 18
				15 00 00 00 14 00 02 39 00
				15 00 00 40 00 00 02 65 01
				15 00 00 00 00 00 02 2C 00
			];
			mi,mdss-dsi-local-hbm-off-to-llpm-command-state = "dsi_hs_mode";

			mi,mdss-dsi-doze-hbm-command = [
				15 00 00 40 00 00 02 5F 01
				39 00 00 40 00 00 05 51 00 00 0F FE
				39 00 00 40 00 00 06 F0 55 AA 52 08 00
				15 00 00 40 00 00 02 B2 18
				15 00 00 00 14 00 02 39 00
				15 00 00 40 00 00 02 65 01
				15 00 00 00 00 00 02 2C 00
			];
			mi,mdss-dsi-doze-hbm-command-state = "dsi_lp_mode";
			mi,mdss-dsi-doze-lbm-command = [
				15 00 00 40 00 00 02 5F 01
				39 00 00 40 00 00 05 51 00 00 01 55
				39 00 00 40 00 00 06 F0 55 AA 52 08 00
				15 00 00 40 00 00 02 B2 18
				15 00 00 00 14 00 02 39 00
				15 00 00 40 00 00 02 65 01
				15 00 00 00 00 00 02 2C 00
			];
			mi,mdss-dsi-doze-lbm-command-state = "dsi_lp_mode";
			mi,mdss-dsi-doze-hbm-nolp-command = [
				39 00 00 00 00 00 06 F0 55 AA 52 08 00
				39 00 00 00 00 00 02 B2 98
				39 00 00 00 00 00 02 65 00
				39 00 00 00 32 00 01 38
				39 00 00 00 00 00 01 2C
			];
			mi,mdss-dsi-doze-hbm-nolp-command-state = "dsi_lp_mode";
			mi,mdss-dsi-doze-lbm-nolp-command = [
				39 00 00 00 00 00 06 F0 55 AA 52 08 00
				39 00 00 00 00 00 02 B2 98
				39 00 00 00 00 00 02 65 00
				39 00 00 00 32 00 01 38
				39 00 00 00 00 00 01 2C
			];
			mi,mdss-dsi-doze-lbm-nolp-command-state = "dsi_lp_mode";

			mi,mdss-dsi-flat-mode-on-command = [
				/* 90Hz gir cmd_1*/
				15 00 00 00 00 00 02 2F 04
				15 00 00 60 00 00 02 5F 00
				39 00 00 60 00 00 06 F0 55 AA 52 08 00
				15 00 00 60 00 00 02 6F 0B
				15 00 00 60 00 00 02 C0 60
				39 00 00 60 00 00 06 F0 55 AA 52 08 02
				15 00 00 60 00 00 02 CC 30
				15 00 00 20 14 00 02 CE 01
			];
			mi,mdss-dsi-flat-mode-on-command-state = "dsi_lp_mode";

			mi,mdss-dsi-flat-mode-on-sec-command = [
				/* 90 Hz gir cmd_2*/
				39 00 00 00 00 00 06 F0 55 AA 52 08 02
				15 00 00 00 00 00 02 CC 00
			];
			mi,mdss-dsi-flat-mode-on-sec-command-state = "dsi_lp_mode";

			mi,mdss-dsi-flat-mode-off-command = [
				/* 90 Hz gir cmd_1*/
				15 00 00 00 00 00 02 2F 04
				15 00 00 60 00 00 02 5F 01
				39 00 00 60 00 00 06 F0 55 AA 52 08 00
				15 00 00 60 00 00 02 6F 0B
				15 00 00 60 00 00 02 C0 20
				39 00 00 60 00 00 06 F0 55 AA 52 08 02
				15 00 00 60 00 00 02 CC 30
				15 00 00 20 14 00 02 CE 01
			];
			mi,mdss-dsi-flat-mode-off-command-state = "dsi_lp_mode";

			mi,mdss-dsi-flat-mode-off-sec-command = [
				/* 90 Hz gir cmd_2*/
				39 00 00 00 00 00 06 F0 55 AA 52 08 02
				15 00 00 00 00 00 02 CC 00
			];
			mi,mdss-dsi-flat-mode-off-sec-command-state = "dsi_lp_mode";

			mi,mdss-dsi-round-corner-on-command = [
				/* Page 07 */
				39 00 00 00 00 00 06 F0 55 AA 52 08 07
				/* Round on */
				39 00 00 00 00 00 02 C0 01
			];
			mi,mdss-dsi-round-corner-on-command-state = "dsi_lp_mode";

			mi,mdss-dsi-round-corner-off-command = [
				/* Page 07 */
				39 00 00 00 00 00 06 F0 55 AA 52 08 07
				/* Round off */
				39 00 00 00 00 00 02 C0 00
			];
			mi,mdss-dsi-round-corner-off-command-state = "dsi_lp_mode";

		};
	};
};
